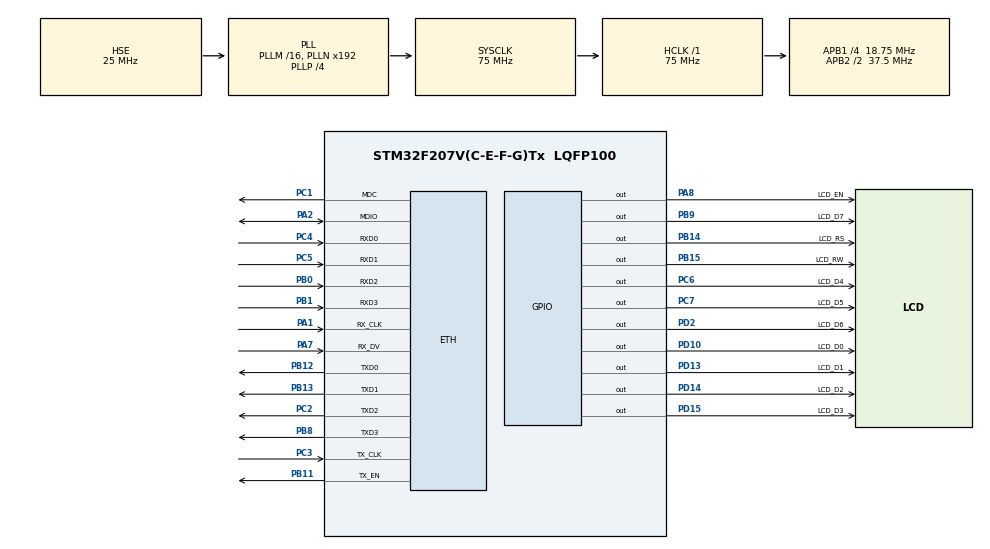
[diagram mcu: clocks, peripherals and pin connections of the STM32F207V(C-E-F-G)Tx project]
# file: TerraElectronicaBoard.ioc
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ETH.MediaInterface=ETH_MEDIA_INTERFACE_MII
ETH.PHY_Name_MII=userPHY
ETH.PHY_User_Name=RTL8201CP
ETH.PhyAddress=31
LWIP.IP_ADDRESS=192.168.124.111
LWIP.LWIP_DHCP=0
LWIP.NETMASK_ADDRESS=255.255.255.000
LWIP.Version=v2.0.3_Cube
Mcu.Family=STM32F2
Mcu.Name=STM32F207V(C-E-F-G)Tx
Mcu.Package=LQFP100
NVIC.PriorityGroup=NVIC_PRIORITYGROUP_4
PA1.Mode=MII Full Duplex Only
PA1.Signal=ETH_RX_CLK
PA2.Mode=MII Full Duplex Only
PA2.Signal=ETH_MDIO
PA7.Mode=MII Full Duplex Only
PA7.Signal=ETH_RX_DV
PA8.GPIO_Label=LCD_EN
PA8.Signal=GPIO_Output
PB0.Mode=MII Full Duplex Only
PB0.Signal=ETH_RXD2
PB1.Mode=MII Full Duplex Only
PB1.Signal=ETH_RXD3
PB11.Mode=MII Full Duplex Only
PB11.Signal=ETH_TX_EN
PB12.Mode=MII Full Duplex Only
PB12.Signal=ETH_TXD0
PB13.Mode=MII Full Duplex Only
PB13.Signal=ETH_TXD1
PB14.GPIO_Label=LCD_RS
PB14.Signal=GPIO_Output
PB15.GPIO_Label=LCD_RW
PB15.Signal=GPIO_Output
PB8.Mode=MII Full Duplex Only
PB8.Signal=ETH_TXD3
PB9.GPIO_Label=LCD_D7
PB9.Signal=GPIO_Output
PC1.Mode=MII Full Duplex Only
PC1.Signal=ETH_MDC
PC2.Mode=MII Full Duplex Only
PC2.Signal=ETH_TXD2
PC3.Mode=MII Full Duplex Only
PC3.Signal=ETH_TX_CLK
PC4.Mode=MII Full Duplex Only
PC4.Signal=ETH_RXD0
PC5.Mode=MII Full Duplex Only
PC5.Signal=ETH_RXD1
PC6.GPIO_Label=LCD_D4
PC6.Signal=GPIO_Output
PC7.GPIO_Label=LCD_D5
PC7.Signal=GPIO_Output
PD10.GPIO_Label=LCD_D0
PD10.Signal=GPIO_Output
PD13.GPIO_Label=LCD_D1
PD13.Signal=GPIO_Output
PD14.GPIO_Label=LCD_D2
PD14.Signal=GPIO_Output
PD15.GPIO_Label=LCD_D3
PD15.Signal=GPIO_Output
PD2.GPIO_Label=LCD_D6
PD2.Signal=GPIO_Output
PH0-OSC_IN.Mode=HSE-External-Oscillator
PH0-OSC_IN.Signal=RCC_OSC_IN
PH1-OSC_OUT.Mode=HSE-External-Oscillator
PH1-OSC_OUT.Signal=RCC_OSC_OUT
ProjectManager.HeapSize=0x200
ProjectManager.StackSize=0x400
ProjectManager.TargetToolchain=Makefile
RCC.48MHZClocksFreq_Value=75000000
RCC.AHBFreq_Value=75000000
RCC.APB1CLKDivider=RCC_HCLK_DIV4
RCC.APB1Freq_Value=18750000
RCC.APB1TimFreq_Value=37500000
RCC.APB2CLKDivider=RCC_HCLK_DIV2
RCC.APB2Freq_Value=37500000
RCC.APB2TimFreq_Value=75000000
RCC.CortexFreq_Value=75000000
RCC.HCLKFreq_Value=75000000
RCC.HSE_VALUE=25000000
RCC.HSI_VALUE=16000000
RCC.LSE_VALUE=32768
RCC.PLLP=RCC_PLLP_DIV4
RCC.PLLSourceVirtual=RCC_PLLSOURCE_HSE
RCC.SYSCLKFreq_VALUE=75000000
RCC.SYSCLKSource=RCC_SYSCLKSOURCE_PLLCLK
RCC.VCOOutputFreq_Value=300000000
VP_LWIP_VS_Enabled.Mode=Enabled
board=custom

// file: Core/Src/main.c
/* USER CODE BEGIN Header */
/**
  ******************************************************************************
  * @file           : main.c
  * @brief          : Main program body
  ******************************************************************************
  * @attention
  *
  * <h2><center>&copy; Copyright (c) 2021 STMicroelectronics.
  * All rights reserved.</center></h2>
  *
  * This software component is licensed by ST under Ultimate Liberty license
  * SLA0044, the "License"; You may not use this file except in compliance with
  * the License. You may obtain a copy of the License at:
  *                             www.st.com/SLA0044
  *
  ******************************************************************************
  */
/* USER CODE END Header */
#include "main.h"
#include "lwip.h"
#include "lcd1602.h"

void SystemClock_Config(void);
static void MX_GPIO_Init(void);

int main(void)
{

  /* MCU Configuration--------------------------------------------------------*/

  /* Reset of all peripherals, Initializes the Flash interface and the Systick. */
  HAL_Init();

  /* Configure the system clock */
  SystemClock_Config();

  /* Initialize all configured peripherals */
  MX_GPIO_Init();
  MX_LWIP_Init();
  /* USER CODE BEGIN 2 */

  //HAL_GPIO_WritePin(TPA_Shutdown_GPIO_Port, TPA_Shutdown_Pin, GPIO_PIN_RESET);
  //HAL_DAC_Start(&hdac, DAC_CHANNEL_1);

  /* USER CODE END 2 */

  /* Infinite loop */
  /* USER CODE BEGIN WHILE */
  init_sequence();
  send_symbol(0b01001000);
  while (1)
  {
    /* USER CODE END WHILE */

    /* USER CODE BEGIN 3 */
    // MX_LWIP_Process();

  }
  /* USER CODE END 3 */
}

void SystemClock_Config(void)
{
  RCC_OscInitTypeDef RCC_OscInitStruct = {0};
  RCC_ClkInitTypeDef RCC_ClkInitStruct = {0};

  /** Initializes the RCC Oscillators according to the specified parameters
  * in the RCC_OscInitTypeDef structure.
  */
  RCC_OscInitStruct.OscillatorType = RCC_OSCILLATORTYPE_HSE;
  RCC_OscInitStruct.HSEState = RCC_HSE_ON;
  RCC_OscInitStruct.PLL.PLLState = RCC_PLL_ON;
  RCC_OscInitStruct.PLL.PLLSource = RCC_PLLSOURCE_HSE;
  RCC_OscInitStruct.PLL.PLLM = 16;
  RCC_OscInitStruct.PLL.PLLN = 192;
  RCC_OscInitStruct.PLL.PLLP = RCC_PLLP_DIV4;
  RCC_OscInitStruct.PLL.PLLQ = 4;
  if (HAL_RCC_OscConfig(&RCC_OscInitStruct) != HAL_OK)
  {
    Error_Handler();
  }
  /** Initializes the CPU, AHB and APB buses clocks
  */
  RCC_ClkInitStruct.ClockType = RCC_CLOCKTYPE_HCLK|RCC_CLOCKTYPE_SYSCLK
                              |RCC_CLOCKTYPE_PCLK1|RCC_CLOCKTYPE_PCLK2;
  RCC_ClkInitStruct.SYSCLKSource = RCC_SYSCLKSOURCE_PLLCLK;
  RCC_ClkInitStruct.AHBCLKDivider = RCC_SYSCLK_DIV1;
  RCC_ClkInitStruct.APB1CLKDivider = RCC_HCLK_DIV4;
  RCC_ClkInitStruct.APB2CLKDivider = RCC_HCLK_DIV2;

  if (HAL_RCC_ClockConfig(&RCC_ClkInitStruct, FLASH_LATENCY_2) != HAL_OK)
  {
    Error_Handler();
  }
}

static void MX_GPIO_Init(void)
{
  GPIO_InitTypeDef GPIO_InitStruct = {0};

  /* GPIO Ports Clock Enable */
  __HAL_RCC_GPIOH_CLK_ENABLE();
  __HAL_RCC_GPIOC_CLK_ENABLE();
  __HAL_RCC_GPIOA_CLK_ENABLE();
  __HAL_RCC_GPIOB_CLK_ENABLE();
  __HAL_RCC_GPIOD_CLK_ENABLE();

  /*Configure GPIO pin Output Level */
  HAL_GPIO_WritePin(GPIOB, LCD_RS_Pin|LCD_RW_Pin|LCD_D7_Pin, GPIO_PIN_RESET);

  /*Configure GPIO pin Output Level */
  HAL_GPIO_WritePin(GPIOD, LCD_D0_Pin|LCD_D1_Pin|LCD_D2_Pin|LCD_D3_Pin
                          |LCD_D6_Pin, GPIO_PIN_RESET);

  /*Configure GPIO pin Output Level */
  HAL_GPIO_WritePin(GPIOC, LCD_D4_Pin|LCD_D5_Pin, GPIO_PIN_RESET);

  /*Configure GPIO pin Output Level */
  HAL_GPIO_WritePin(LCD_EN_GPIO_Port, LCD_EN_Pin, GPIO_PIN_RESET);

  /*Configure GPIO pins : LCD_RS_Pin LCD_RW_Pin LCD_D7_Pin */
  GPIO_InitStruct.Pin = LCD_RS_Pin|LCD_RW_Pin|LCD_D7_Pin;
  GPIO_InitStruct.Mode = GPIO_MODE_OUTPUT_PP;
  GPIO_InitStruct.Pull = GPIO_NOPULL;
  GPIO_InitStruct.Speed = GPIO_SPEED_FREQ_LOW;
  HAL_GPIO_Init(GPIOB, &GPIO_InitStruct);

  /*Configure GPIO pins : LCD_D0_Pin LCD_D1_Pin LCD_D2_Pin LCD_D3_Pin
                           LCD_D6_Pin */
  GPIO_InitStruct.Pin = LCD_D0_Pin|LCD_D1_Pin|LCD_D2_Pin|LCD_D3_Pin
                          |LCD_D6_Pin;
  GPIO_InitStruct.Mode = GPIO_MODE_OUTPUT_PP;
  GPIO_InitStruct.Pull = GPIO_NOPULL;
  GPIO_InitStruct.Speed = GPIO_SPEED_FREQ_LOW;
  HAL_GPIO_Init(GPIOD, &GPIO_InitStruct);

  /*Configure GPIO pins : LCD_D4_Pin LCD_D5_Pin */
  GPIO_InitStruct.Pin = LCD_D4_Pin|LCD_D5_Pin;
  GPIO_InitStruct.Mode = GPIO_MODE_OUTPUT_PP;
  GPIO_InitStruct.Pull = GPIO_NOPULL;
  GPIO_InitStruct.Speed = GPIO_SPEED_FREQ_LOW;
  HAL_GPIO_Init(GPIOC, &GPIO_InitStruct);

  /*Configure GPIO pin : LCD_EN_Pin */
  GPIO_InitStruct.Pin = LCD_EN_Pin;
  GPIO_InitStruct.Mode = GPIO_MODE_OUTPUT_PP;
  GPIO_InitStruct.Pull = GPIO_NOPULL;
  GPIO_InitStruct.Speed = GPIO_SPEED_FREQ_LOW;
  HAL_GPIO_Init(LCD_EN_GPIO_Port, &GPIO_InitStruct);

}

void Error_Handler(void)
{
  __disable_irq();
  while (1)
  {
  }
}

/************************ (C) COPYRIGHT STMicroelectronics *****END OF FILE****/
